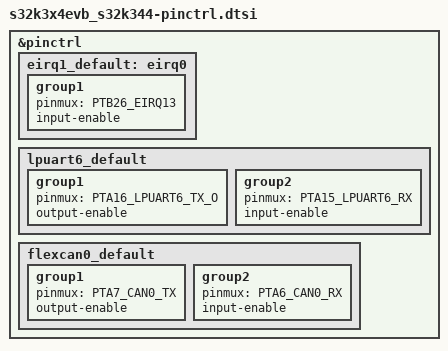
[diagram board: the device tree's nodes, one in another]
/*
 * SPDX-FileCopyrightText: Copyright (c) 2026 Sachin Kumar
 *
 * SPDX-License-Identifier: Apache-2.0
 */

#include <zephyr/dt-bindings/pinctrl/nxp-siul2-pinctrl.h>
#include <nxp/s32/S32K344-172MQFP-pinctrl.h>

&pinctrl {
	eirq1_default: eirq0 {
		group1 {
			pinmux = <PTB26_EIRQ13>;
			input-enable;
		};
	};

	lpuart6_default: lpuart6_default {
		group1 {
			pinmux = <PTA16_LPUART6_TX_O>;
			output-enable;
		};
		group2 {
			pinmux = <PTA15_LPUART6_RX>;
			input-enable;
		};
	};
	flexcan0_default: flexcan0_default {
		group1 {
			pinmux = <PTA7_CAN0_TX>;
			output-enable;
		};
		group2 {
			pinmux = <PTA6_CAN0_RX>;
			input-enable;
		};
	};
};
